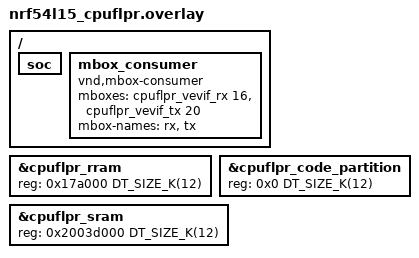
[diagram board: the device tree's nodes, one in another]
/*
 * Copyright (c) 2024 Nordic Semiconductor ASA
 *
 * SPDX-License-Identifier: LicenseRef-Nordic-5-Clause
 */

/ {
	soc {
		/* No shared SRAM needed - data passed directly via MBOX messages */
	};

	mbox_consumer: mbox_consumer {
		compatible = "vnd,mbox-consumer";
		mboxes = <&cpuflpr_vevif_rx 16>, <&cpuflpr_vevif_tx 20>;
		mbox-names = "rx", "tx";
	};
};

&cpuflpr_rram {
	reg = <0x17a000 DT_SIZE_K(12)>;
};

&cpuflpr_code_partition {
	reg = <0x0 DT_SIZE_K(12)>;
};

&cpuflpr_sram {
	reg = <0x2003d000 DT_SIZE_K(12)>;
	ranges = <0x0 0x2003d000 0x3000>;
};
